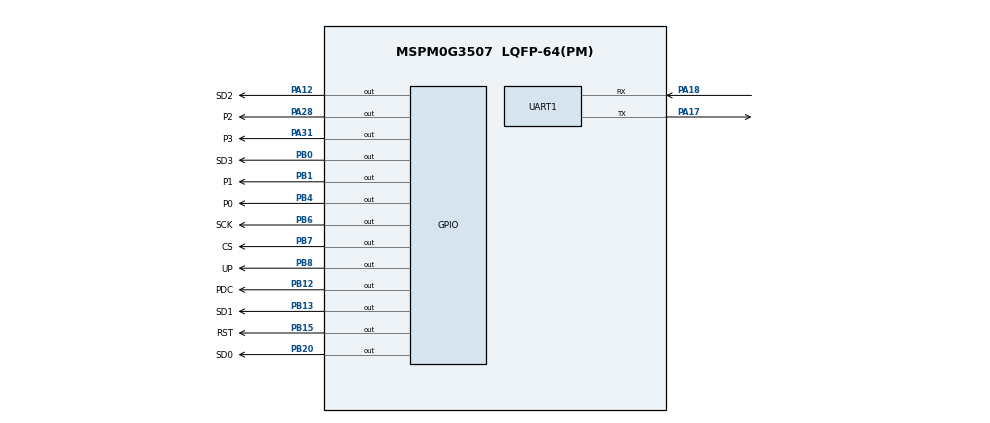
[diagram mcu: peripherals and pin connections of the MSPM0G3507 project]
/**
 * These arguments were used when this file was generated. They will be automatically applied on subsequent loads
 * via the GUI or CLI. Run CLI with '--help' for additional information on how to override these arguments.
 * @cliArgs --device "MSPM0G350X" --part "Default" --package "LQFP-64(PM)" --product "mspm0_sdk@2.04.00.06"
 * @v2CliArgs --device "MSPM0G3507" --package "LQFP-64(PM)" --product "mspm0_sdk@2.04.00.06"
 * @versions {"tool":"1.23.0+4000"}
 */

/**
 * Import the modules used in this configuration.
 */
const ADC12         = scripting.addModule("/ti/driverlib/ADC12", {}, false);
const ADC121        = ADC12.addInstance();
const ADC122        = ADC12.addInstance();
const GPIO          = scripting.addModule("/ti/driverlib/GPIO", {}, false);
const GPIO1         = GPIO.addInstance();
const SYSCTL        = scripting.addModule("/ti/driverlib/SYSCTL");
const TIMER         = scripting.addModule("/ti/driverlib/TIMER", {}, false);
const TIMER1        = TIMER.addInstance();
const UART          = scripting.addModule("/ti/driverlib/UART", {}, false);
const UART1         = UART.addInstance();
const ProjectConfig = scripting.addModule("/ti/project_config/ProjectConfig");

/**
 * Write custom configuration values to the imported modules.
 */
ADC121.$name                             = "ADC12_0";
ADC121.trigSrc                           = "DL_ADC12_TRIG_SRC_EVENT";
ADC121.repeatMode                        = true;
ADC121.adcMem0trig                       = "DL_ADC12_TRIGGER_MODE_TRIGGER_NEXT";
ADC121.powerDownMode                     = "DL_ADC12_POWER_DOWN_MODE_MANUAL";
ADC121.sampleTime0                       = "62.5ns";
ADC121.enabledInterrupts                 = ["DL_ADC12_INTERRUPT_DMA_DONE"];
ADC121.configureDMA                      = true;
ADC121.enabledDMATriggers                = ["DL_ADC12_DMA_MEM0_RESULT_LOADED"];
ADC121.sampCnt                           = 1;
ADC121.subChanID                         = 12;
ADC121.adcMem0chansel                    = "DL_ADC12_INPUT_CHAN_4";
ADC121.DMA_CHANNEL.$name                 = "DMA_CH0";
ADC121.DMA_CHANNEL.addressMode           = "f2b";
ADC121.DMA_CHANNEL.srcLength             = "HALF_WORD";
ADC121.DMA_CHANNEL.dstLength             = "HALF_WORD";
ADC121.DMA_CHANNEL.configureTransferSize = true;
ADC121.DMA_CHANNEL.transferSize          = 1024;
ADC121.DMA_CHANNEL.peripheral.$assign    = "DMA_CH0";
ADC121.peripheral.$assign                = "ADC0";
ADC121.adcPin4Config.$name               = "ti_driverlib_gpio_GPIOPinGeneric0";

ADC122.$name                             = "ADC12_1";
ADC122.repeatMode                        = true;
ADC122.trigSrc                           = "DL_ADC12_TRIG_SRC_EVENT";
ADC122.adcMem0trig                       = "DL_ADC12_TRIGGER_MODE_TRIGGER_NEXT";
ADC122.powerDownMode                     = "DL_ADC12_POWER_DOWN_MODE_MANUAL";
ADC122.sampleTime0                       = "62.5ns";
ADC122.enabledInterrupts                 = ["DL_ADC12_INTERRUPT_DMA_DONE"];
ADC122.configureDMA                      = true;
ADC122.sampCnt                           = 1;
ADC122.enabledDMATriggers                = ["DL_ADC12_DMA_MEM0_RESULT_LOADED"];
ADC122.subChanID                         = 12;
ADC122.adcMem0chansel                    = "DL_ADC12_INPUT_CHAN_4";
ADC122.DMA_CHANNEL.$name                 = "DMA_CH1";
ADC122.DMA_CHANNEL.addressMode           = "f2b";
ADC122.DMA_CHANNEL.srcLength             = "HALF_WORD";
ADC122.DMA_CHANNEL.dstLength             = "HALF_WORD";
ADC122.DMA_CHANNEL.configureTransferSize = true;
ADC122.DMA_CHANNEL.transferSize          = 1024;
ADC122.DMA_CHANNEL.peripheral.$assign    = "DMA_CH1";
ADC122.peripheral.$assign                = "ADC1";
ADC122.adcPin4Config.$name               = "ti_driverlib_gpio_GPIOPinGeneric1";

const Board = scripting.addModule("/ti/driverlib/Board", {}, false);

GPIO1.$name                          = "AD9959";
GPIO1.associatedPins.create(13);
GPIO1.associatedPins[0].$name        = "PDC";
GPIO1.associatedPins[0].pin.$assign  = "PB12";
GPIO1.associatedPins[1].$name        = "RST";
GPIO1.associatedPins[1].pin.$assign  = "PB15";
GPIO1.associatedPins[2].$name        = "SD3";
GPIO1.associatedPins[2].pin.$assign  = "PB0";
GPIO1.associatedPins[3].$name        = "SD2";
GPIO1.associatedPins[3].pin.$assign  = "PA12";
GPIO1.associatedPins[4].$name        = "SD1";
GPIO1.associatedPins[4].pin.$assign  = "PB13";
GPIO1.associatedPins[5].$name        = "SD0";
GPIO1.associatedPins[5].pin.$assign  = "PB20";
GPIO1.associatedPins[6].$name        = "SCK";
GPIO1.associatedPins[6].pin.$assign  = "PB6";
GPIO1.associatedPins[7].$name        = "CS";
GPIO1.associatedPins[7].pin.$assign  = "PB7";
GPIO1.associatedPins[8].$name        = "UP";
GPIO1.associatedPins[8].pin.$assign  = "PB8";
GPIO1.associatedPins[9].$name        = "P2";
GPIO1.associatedPins[9].pin.$assign  = "PA28";
GPIO1.associatedPins[10].$name       = "P3";
GPIO1.associatedPins[10].pin.$assign = "PA31";
GPIO1.associatedPins[11].$name       = "P0";
GPIO1.associatedPins[11].pin.$assign = "PB4";
GPIO1.associatedPins[12].$name       = "P1";
GPIO1.associatedPins[12].pin.$assign = "PB1";

SYSCTL.forceDefaultClkConfig = true;
SYSCTL.clockTreeEn           = true;

TIMER1.$name                       = "TIMER_0";
TIMER1.timerMode                   = "PERIODIC";
TIMER1.timerPeriod                 = "1us";
TIMER1.interrupts                  = ["ZERO"];
TIMER1.event1ControllerInterruptEn = ["ZERO_EVENT"];
TIMER1.event2ControllerInterruptEn = ["ZERO_EVENT"];
TIMER1.timerStartTimer             = true;
TIMER1.event1PublisherChannel      = 12;

UART1.$name                            = "UART_1";
UART1.rxFifoThreshold                  = "DL_UART_RX_FIFO_LEVEL_ONE_ENTRY";
UART1.enabledInterrupts                = ["RX"];
UART1.enableFIFO                       = true;
UART1.peripheral.$assign               = "UART1";
UART1.peripheral.rxPin.$assign         = "PA18";
UART1.peripheral.txPin.$assign         = "PA17";
UART1.txPinConfig.$name                = "ti_driverlib_gpio_GPIOPinGeneric2";
UART1.txPinConfig.direction            = scripting.forceWrite("OUTPUT");
UART1.txPinConfig.hideOutputInversion  = scripting.forceWrite(false);
UART1.txPinConfig.onlyInternalResistor = scripting.forceWrite(false);
UART1.txPinConfig.passedPeripheralType = scripting.forceWrite("Digital");
UART1.rxPinConfig.$name                = "ti_driverlib_gpio_GPIOPinGeneric3";
UART1.rxPinConfig.hideOutputInversion  = scripting.forceWrite(false);
UART1.rxPinConfig.onlyInternalResistor = scripting.forceWrite(false);
UART1.rxPinConfig.passedPeripheralType = scripting.forceWrite("Digital");

ProjectConfig.genLibCMSIS = true;

/**
 * Pinmux solution for unlocked pins/peripherals. This ensures that minor changes to the automatic solver in a future
 * version of the tool will not impact the pinmux you originally saw.  These lines can be completely deleted in order to
 * re-solve from scratch.
 */
ADC121.peripheral.adcPin4.$suggestSolution = "PB25";
ADC122.peripheral.adcPin4.$suggestSolution = "PB17";
Board.peripheral.$suggestSolution          = "DEBUGSS";
Board.peripheral.swclkPin.$suggestSolution = "PA20";
Board.peripheral.swdioPin.$suggestSolution = "PA19";
TIMER1.peripheral.$suggestSolution         = "TIMA0";
